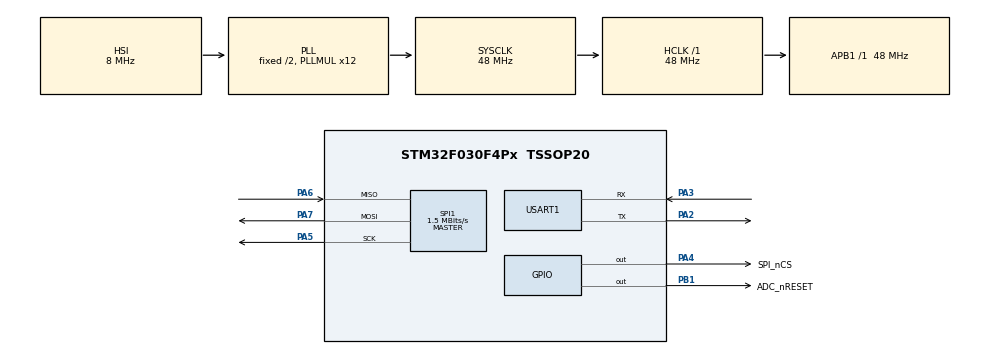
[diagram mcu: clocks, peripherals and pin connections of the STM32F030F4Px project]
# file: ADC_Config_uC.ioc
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Mcu.Family=STM32F0
Mcu.Name=STM32F030F4Px
Mcu.Package=TSSOP20
PA13.Mode=Serial_Wire
PA13.Signal=SYS_SWDIO
PA14.Mode=Serial_Wire
PA14.Signal=SYS_SWCLK
PA2.Mode=Asynchronous
PA2.Signal=USART1_TX
PA3.Mode=Asynchronous
PA3.Signal=USART1_RX
PA4.GPIO_Label=SPI_nCS
PA4.Signal=GPIO_Output
PA5.Mode=Full_Duplex_Master
PA5.Signal=SPI1_SCK
PA6.Mode=Full_Duplex_Master
PA6.Signal=SPI1_MISO
PA7.Mode=Full_Duplex_Master
PA7.Signal=SPI1_MOSI
PB1.GPIO_Label=ADC_nRESET
PB1.Signal=GPIO_Output
ProjectManager.HeapSize=0x200
ProjectManager.StackSize=0x400
ProjectManager.TargetToolchain=STM32CubeIDE
RCC.AHBFreq_Value=48000000
RCC.APB1Freq_Value=48000000
RCC.APB1TimFreq_Value=48000000
RCC.HCLKFreq_Value=48000000
RCC.PLLMUL=RCC_PLL_MUL12
RCC.SYSCLKFreq_VALUE=48000000
RCC.SYSCLKSource=RCC_SYSCLKSOURCE_PLLCLK
SPI1.BaudRatePrescaler=SPI_BAUDRATEPRESCALER_32
SPI1.CalculateBaudRate=1.5 MBits/s
SPI1.DataSize=SPI_DATASIZE_8BIT
SPI1.Direction=SPI_DIRECTION_2LINES
SPI1.Mode=SPI_MODE_MASTER
SPI1.VirtualType=VM_MASTER
USART1.VirtualMode-Asynchronous=VM_ASYNC
board=custom

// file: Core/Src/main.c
/* USER CODE BEGIN Header */
/**
  ******************************************************************************
  * @file           : main.c
  * @brief          : Main program body
  ******************************************************************************
  * @attention
  *
  * <h2><center>&copy; Copyright (c) 2020 STMicroelectronics.
  * All rights reserved.</center></h2>
  *
  * This software component is licensed by ST under BSD 3-Clause license,
  * the "License"; You may not use this file except in compliance with the
  * License. You may obtain a copy of the License at:
  *                        opensource.org/licenses/BSD-3-Clause
  *
  ******************************************************************************
  */
/* USER CODE END Header */

#include "main.h"

/* USER CODE BEGIN Includes */

#include "AD7779.h"

/* USER CODE END Includes */

SPI_HandleTypeDef hspi1;

UART_HandleTypeDef huart1;

void SystemClock_Config(void);
static void MX_GPIO_Init(void);
static void MX_SPI1_Init(void);
static void MX_USART1_UART_Init(void);

int main(void)
{

  /* MCU Configuration--------------------------------------------------------*/

  /* Reset of all peripherals, Initializes the Flash interface and the Systick. */
  HAL_Init();

  /* Configure the system clock */
  SystemClock_Config();

  /* Initialize all configured peripherals */
  MX_GPIO_Init();
  MX_SPI1_Init();
  MX_USART1_UART_Init();
  /* USER CODE BEGIN 2 */
  AD7779_init(&hspi1);

  /* USER CODE END 2 */

  /* Infinite loop */
  /* USER CODE BEGIN WHILE */
  while (1)
  {
	  HAL_Delay(500);

    /* USER CODE END WHILE */

  }
}

void SystemClock_Config(void)
{
  RCC_OscInitTypeDef RCC_OscInitStruct = {0};
  RCC_ClkInitTypeDef RCC_ClkInitStruct = {0};
  RCC_PeriphCLKInitTypeDef PeriphClkInit = {0};

  /** Initializes the CPU, AHB and APB busses clocks
  */
  RCC_OscInitStruct.OscillatorType = RCC_OSCILLATORTYPE_HSI;
  RCC_OscInitStruct.HSIState = RCC_HSI_ON;
  RCC_OscInitStruct.HSICalibrationValue = RCC_HSICALIBRATION_DEFAULT;
  RCC_OscInitStruct.PLL.PLLState = RCC_PLL_ON;
  RCC_OscInitStruct.PLL.PLLSource = RCC_PLLSOURCE_HSI;
  RCC_OscInitStruct.PLL.PLLMUL = RCC_PLL_MUL12;
  RCC_OscInitStruct.PLL.PREDIV = RCC_PREDIV_DIV1;
  if (HAL_RCC_OscConfig(&RCC_OscInitStruct) != HAL_OK)
  {
    Error_Handler();
  }
  /** Initializes the CPU, AHB and APB busses clocks
  */
  RCC_ClkInitStruct.ClockType = RCC_CLOCKTYPE_HCLK|RCC_CLOCKTYPE_SYSCLK
                              |RCC_CLOCKTYPE_PCLK1;
  RCC_ClkInitStruct.SYSCLKSource = RCC_SYSCLKSOURCE_PLLCLK;
  RCC_ClkInitStruct.AHBCLKDivider = RCC_SYSCLK_DIV1;
  RCC_ClkInitStruct.APB1CLKDivider = RCC_HCLK_DIV1;

  if (HAL_RCC_ClockConfig(&RCC_ClkInitStruct, FLASH_LATENCY_1) != HAL_OK)
  {
    Error_Handler();
  }
  PeriphClkInit.PeriphClockSelection = RCC_PERIPHCLK_USART1;
  PeriphClkInit.Usart1ClockSelection = RCC_USART1CLKSOURCE_PCLK1;
  if (HAL_RCCEx_PeriphCLKConfig(&PeriphClkInit) != HAL_OK)
  {
    Error_Handler();
  }
}

static void MX_SPI1_Init(void)
{

  /* SPI1 parameter configuration*/
  hspi1.Instance = SPI1;
  hspi1.Init.Mode = SPI_MODE_MASTER;
  hspi1.Init.Direction = SPI_DIRECTION_2LINES;
  hspi1.Init.DataSize = SPI_DATASIZE_8BIT;
  hspi1.Init.CLKPolarity = SPI_POLARITY_LOW;
  hspi1.Init.CLKPhase = SPI_PHASE_1EDGE;
  hspi1.Init.NSS = SPI_NSS_SOFT;
  hspi1.Init.BaudRatePrescaler = SPI_BAUDRATEPRESCALER_32;
  hspi1.Init.FirstBit = SPI_FIRSTBIT_MSB;
  hspi1.Init.TIMode = SPI_TIMODE_DISABLE;
  hspi1.Init.CRCCalculation = SPI_CRCCALCULATION_DISABLE;
  hspi1.Init.CRCPolynomial = 7;
  hspi1.Init.CRCLength = SPI_CRC_LENGTH_DATASIZE;
  hspi1.Init.NSSPMode = SPI_NSS_PULSE_ENABLE;
  if (HAL_SPI_Init(&hspi1) != HAL_OK)
  {
    Error_Handler();
  }

}

static void MX_USART1_UART_Init(void)
{

  huart1.Instance = USART1;
  huart1.Init.BaudRate = 38400;
  huart1.Init.WordLength = UART_WORDLENGTH_8B;
  huart1.Init.StopBits = UART_STOPBITS_1;
  huart1.Init.Parity = UART_PARITY_NONE;
  huart1.Init.Mode = UART_MODE_TX_RX;
  huart1.Init.HwFlowCtl = UART_HWCONTROL_NONE;
  huart1.Init.OverSampling = UART_OVERSAMPLING_16;
  huart1.Init.OneBitSampling = UART_ONE_BIT_SAMPLE_DISABLE;
  huart1.AdvancedInit.AdvFeatureInit = UART_ADVFEATURE_NO_INIT;
  if (HAL_UART_Init(&huart1) != HAL_OK)
  {
    Error_Handler();
  }

}

static void MX_GPIO_Init(void)
{
  GPIO_InitTypeDef GPIO_InitStruct = {0};

  /* GPIO Ports Clock Enable */
  __HAL_RCC_GPIOA_CLK_ENABLE();
  __HAL_RCC_GPIOB_CLK_ENABLE();

  /*Configure GPIO pin Output Level */
  HAL_GPIO_WritePin(SPI_nCS_GPIO_Port, SPI_nCS_Pin, GPIO_PIN_RESET);

  /*Configure GPIO pin Output Level */
  HAL_GPIO_WritePin(ADC_nRESET_GPIO_Port, ADC_nRESET_Pin, GPIO_PIN_RESET);

  /*Configure GPIO pin : SPI_nCS_Pin */
  GPIO_InitStruct.Pin = SPI_nCS_Pin;
  GPIO_InitStruct.Mode = GPIO_MODE_OUTPUT_PP;
  GPIO_InitStruct.Pull = GPIO_NOPULL;
  GPIO_InitStruct.Speed = GPIO_SPEED_FREQ_LOW;
  HAL_GPIO_Init(SPI_nCS_GPIO_Port, &GPIO_InitStruct);

  /*Configure GPIO pin : ADC_nRESET_Pin */
  GPIO_InitStruct.Pin = ADC_nRESET_Pin;
  GPIO_InitStruct.Mode = GPIO_MODE_OUTPUT_PP;
  GPIO_InitStruct.Pull = GPIO_NOPULL;
  GPIO_InitStruct.Speed = GPIO_SPEED_FREQ_LOW;
  HAL_GPIO_Init(ADC_nRESET_GPIO_Port, &GPIO_InitStruct);

}

void Error_Handler(void)
{
}

/************************ (C) COPYRIGHT STMicroelectronics *****END OF FILE****/
